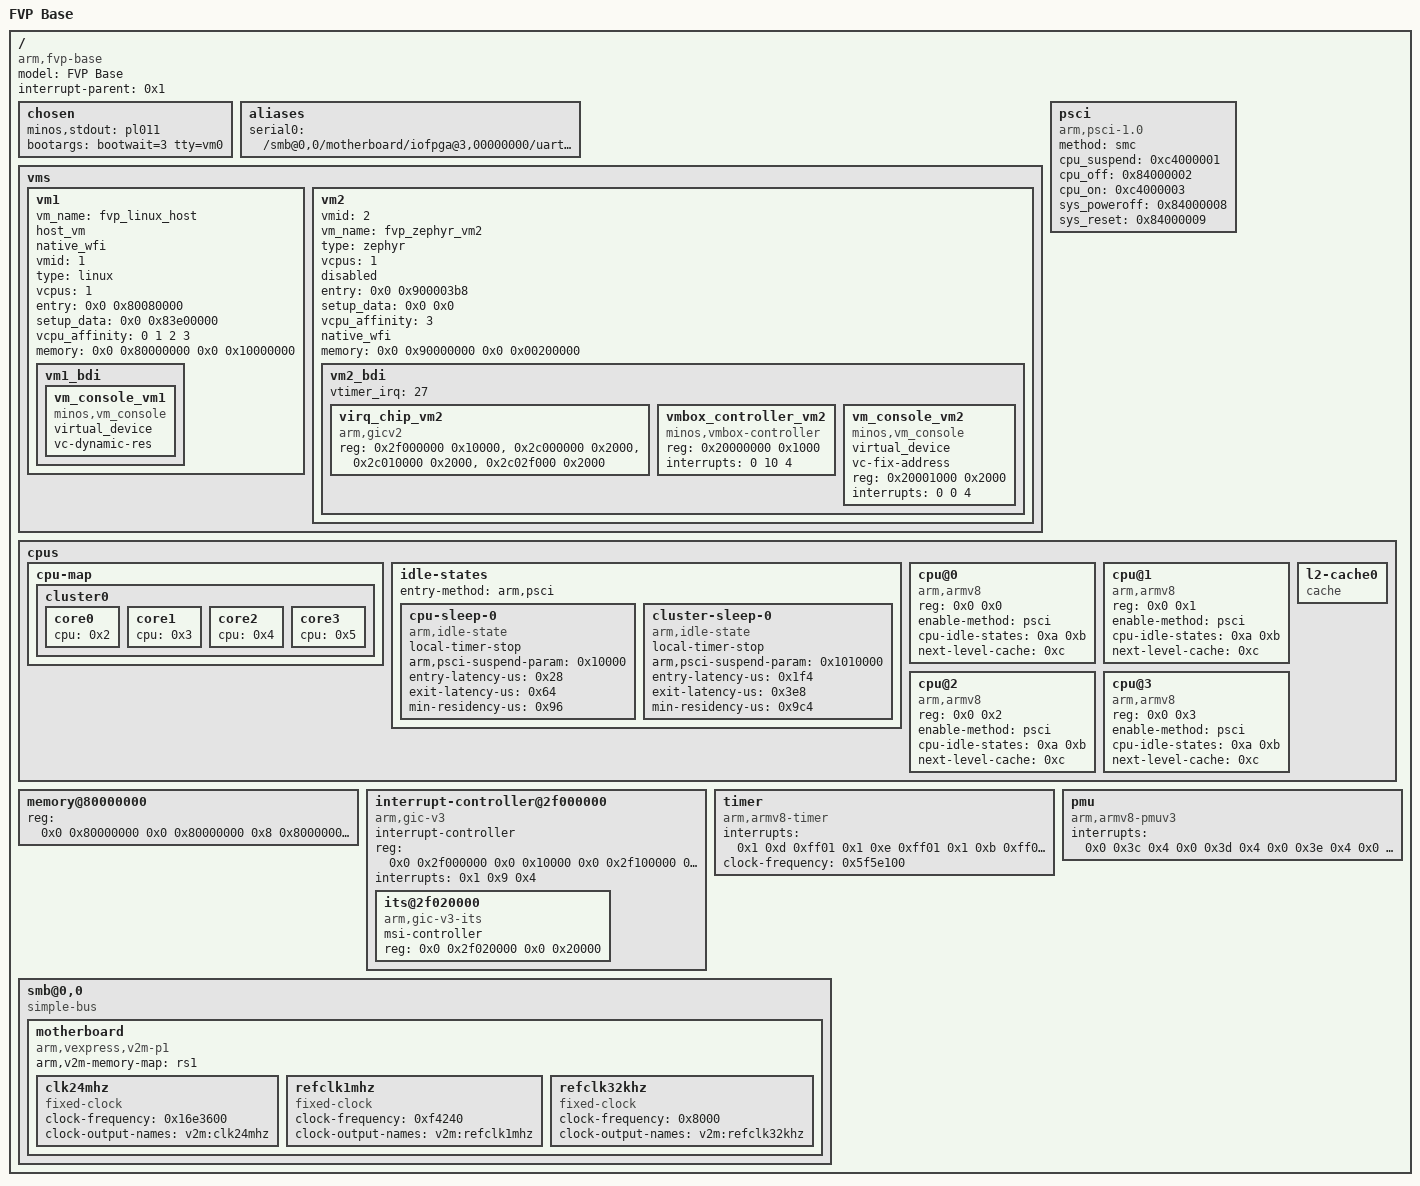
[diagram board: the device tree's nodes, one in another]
/dts-v1/;

/ {
	model = "FVP Base";
	compatible = "arm,fvp-base", "arm,vexpress";
	interrupt-parent = <0x1>;
	#address-cells = <0x2>;
	#size-cells = <0x2>;

	chosen {
		minos,stdout = "pl011";
		bootargs = "bootwait=3 tty=vm0";
	};

	aliases {
		serial0 = "/smb@0,0/motherboard/iofpga@3,00000000/uart@90000";
	};

	vms {
		vm1 {
			device_type = "virtual_machine";
			vm_name = "fvp_linux_host";
			host_vm;
			native_wfi;
			vmid = <1>;
			type = "linux";
			vcpus = <1>;
			entry = <0x0 0x80080000>;
			setup_data = <0x0 0x83e00000>;
			vcpu_affinity = <0 1 2 3>;
			/* cmdline = "console=hvc0 earlycon=dbcon,io,0x0 loglevel=8 consolelog=9 root=/dev/vda2 rw"; */
			memory = <0x0 0x80000000 0x0 0x10000000>;

			vm1_bdi {
				vm_console_vm1 {
					virtual_device;
					vc-dynamic-res;
					compatible = "minos,vm_console";
				};
			};
		};

		vm2 {
			device_type = "virtual_machine";
			vmid = <2>;
			vm_name = "fvp_zephyr_vm2";
			type = "zephyr";
			vcpus = <1>;
			disabled;
			entry = <0x0 0x900003b8>;
			setup_data = <0x0 0x0>;
			vcpu_affinity = <3>;
			native_wfi;
			memory = <0x0 0x90000000 0x0 0x00200000>;

			vm2_bdi {
				#address-cells = <0x1>;
				#size-cells = <0x1>;

				vtimer_irq = <27>;

				virq_chip_vm2 {
					compatible = "arm,gicv2";
					#address-cells = <0x1>;
					#size-cells = <0x1>;
					reg = <0x2f000000 0x10000>,
						<0x2c000000 0x2000>,
						<0x2c010000 0x2000>,
						<0x2c02f000 0x2000>;
				};

				vmbox_controller_vm2 {
					compatible = "minos,vmbox-controller";
					reg = <0x20000000 0x1000>;
					interrupts = <0 10 4>;
				};

				vm_console_vm2 {
					virtual_device;
					vc-fix-address;
					compatible = "minos,vm_console";
					reg = <0x20001000 0x2000>;
					interrupts = <0 0 4>;
				};
			};
		};

	};

	psci {
		compatible = "arm,psci-1.0", "arm,psci-0.2", "arm,psci";
		method = "smc";
		cpu_suspend = <0xc4000001>;
		cpu_off = <0x84000002>;
		cpu_on = <0xc4000003>;
		sys_poweroff = <0x84000008>;
		sys_reset = <0x84000009>;
	};

	cpus {
		#address-cells = <0x2>;
		#size-cells = <0x0>;

		cpu-map {

			cluster0 {

				core0 {
					cpu = <0x2>;
				};

				core1 {
					cpu = <0x3>;
				};

				core2 {
					cpu = <0x4>;
				};

				core3 {
					cpu = <0x5>;
				};
			};
		};

		idle-states {
			entry-method = "arm,psci";

			cpu-sleep-0 {
				compatible = "arm,idle-state";
				local-timer-stop;
				arm,psci-suspend-param = <0x10000>;
				entry-latency-us = <0x28>;
				exit-latency-us = <0x64>;
				min-residency-us = <0x96>;
				linux,phandle = <0xa>;
				phandle = <0xa>;
			};

			cluster-sleep-0 {
				compatible = "arm,idle-state";
				local-timer-stop;
				arm,psci-suspend-param = <0x1010000>;
				entry-latency-us = <0x1f4>;
				exit-latency-us = <0x3e8>;
				min-residency-us = <0x9c4>;
				linux,phandle = <0xb>;
				phandle = <0xb>;
			};
		};

		cpu@0 {
			device_type = "cpu";
			compatible = "arm,armv8";
			reg = <0x0 0x0>;
			enable-method = "psci";
			cpu-idle-states = <0xa 0xb>;
			next-level-cache = <0xc>;
			linux,phandle = <0x2>;
			phandle = <0x2>;
		};

		cpu@1 {
			device_type = "cpu";
			compatible = "arm,armv8";
			reg = <0x0 0x1>;
			enable-method = "psci";
			cpu-idle-states = <0xa 0xb>;
			next-level-cache = <0xc>;
			linux,phandle = <0x3>;
			phandle = <0x3>;
		};

		cpu@2 {
			device_type = "cpu";
			compatible = "arm,armv8";
			reg = <0x0 0x2>;
			enable-method = "psci";
			cpu-idle-states = <0xa 0xb>;
			next-level-cache = <0xc>;
			linux,phandle = <0x4>;
			phandle = <0x4>;
		};

		cpu@3 {
			device_type = "cpu";
			compatible = "arm,armv8";
			reg = <0x0 0x3>;
			enable-method = "psci";
			cpu-idle-states = <0xa 0xb>;
			next-level-cache = <0xc>;
			linux,phandle = <0x5>;
			phandle = <0x5>;
		};

		l2-cache0 {
			compatible = "cache";
			linux,phandle = <0xc>;
			phandle = <0xc>;
		};
	};

	memory@80000000 {
		device_type = "memory";
		reg = <0x0 0x80000000 0x0 0x80000000 0x8 0x80000000 0x0 0x80000000>;
	};

	interrupt-controller@2f000000 {
		compatible = "arm,gic-v3";
		#interrupt-cells = <0x3>;
		#address-cells = <0x2>;
		#size-cells = <0x2>;
		ranges;
		interrupt-controller;
		reg = <0x0 0x2f000000 0x0 0x10000 0x0 0x2f100000 0x0 0x200000 0x0 0x2c000000 0x0 0x2000 0x0 0x2c010000 0x0 0x2000 0x0 0x2c02f000 0x0 0x2000>;
		interrupts = <0x1 0x9 0x4>;
		linux,phandle = <0x1>;
		phandle = <0x1>;

		its@2f020000 {
			compatible = "arm,gic-v3-its";
			msi-controller;
			reg = <0x0 0x2f020000 0x0 0x20000>;
		};
	};

	timer {
		compatible = "arm,armv8-timer";
		interrupts = <0x1 0xd 0xff01 0x1 0xe 0xff01 0x1 0xb 0xff01 0x1 0xa 0xff01>;
		clock-frequency = <0x5f5e100>;
	};

	pmu {
		compatible = "arm,armv8-pmuv3";
		interrupts = <0x0 0x3c 0x4 0x0 0x3d 0x4 0x0 0x3e 0x4 0x0 0x3f 0x4>;
	};

	smb@0,0 {
		compatible = "simple-bus";
		#address-cells = <0x2>;
		#size-cells = <0x1>;
		ranges = <0x0 0x0 0x0 0x8000000 0x4000000 0x1 0x0 0x0 0x14000000 0x4000000 0x2 0x0 0x0 0x18000000 0x4000000 0x3 0x0 0x0 0x1c000000 0x4000000 0x4 0x0 0x0 0xc000000 0x4000000 0x5 0x0 0x0 0x10000000 0x4000000>;

		motherboard {
			arm,v2m-memory-map = "rs1";
			compatible = "arm,vexpress,v2m-p1", "simple-bus";
			#address-cells = <0x2>;
			#size-cells = <0x1>;
			ranges;

			clk24mhz {
				compatible = "fixed-clock";
				#clock-cells = <0x0>;
				clock-frequency = <0x16e3600>;
				clock-output-names = "v2m:clk24mhz";
				linux,phandle = <0xf>;
				phandle = <0xf>;
			};

			refclk1mhz {
				compatible = "fixed-clock";
				#clock-cells = <0x0>;
				clock-frequency = <0xf4240>;
				clock-output-names = "v2m:refclk1mhz";
				linux,phandle = <0xe>;
				phandle = <0xe>;
			};

			refclk32khz {
				compatible = "fixed-clock";
				#clock-cells = <0x0>;
				clock-frequency = <0x8000>;
				clock-output-names = "v2m:refclk32khz";
				linux,phandle = <0xd>;
				phandle = <0xd>;
			};

		};
	};
};
